# STM32WL5x_CM4 register map
File version: 1.9
CPU: CM4 r0p1, little endian, MPU, FPU, 4 interrupt priority bits
Registers are 32-bit, read-write, reset 0x0 unless marked. A register's access mark holds for its fields unless they carry their own. Offsets are from the block's base; [hi:lo] are bit positions; {n}, {i} and the like mark numbered series; 'fields as' and 'values as' point back to an identical list.

## GPIOH — General-purpose I/Os
Base 0x48001C00
0x00 MODER reset 0xC0 — GPIO port mode register
  [7:6] MODER3 — Port x configuration bits (y = 0..15)
0x04 OTYPER — GPIO port output type register
  [3] OT3 — Port x configuration bits (y = 0..15)
0x08 OSPEEDR — GPIO port output speed register
  [7:6] OSPEEDR3 — Port x configuration bits (y = 0..15)
0x0C PUPDR — GPIO port pull-up/pull-down register
  [7:6] PUPDR3 — Port x configuration bits (y = 0..15)
0x10 IDR ro — GPIO port input data register
  [3] IDR3 — Port input data (y = 0..15)
0x14 ODR — GPIO port output data register
  [3] ODR3 — Port output data (y = 0..15)
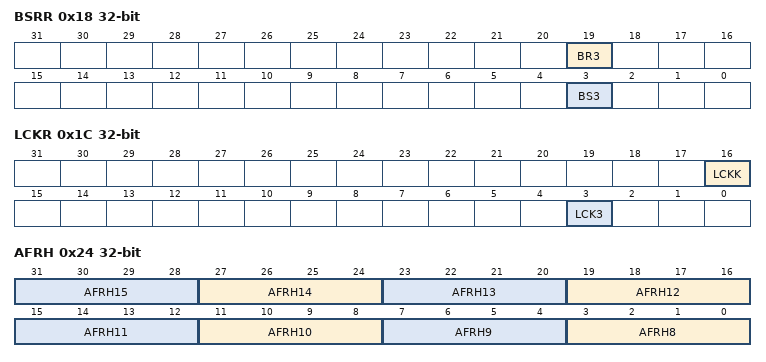
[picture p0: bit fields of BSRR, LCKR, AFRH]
0x18 BSRR wo — GPIO port bit set/reset register
  [19] BR3 — Port x reset bit y (y = 0..15)
  [3] BS3 — Port x set bit y (y= 0..15)
0x1C LCKR — GPIO port configuration lock register
  [16] LCKK — Port x lock bit y (y= 0..15)
  [3] LCK3 — Port x lock bit y (y= 0..15)
0x20 AFRL — GPIO alternate function low register
  [15:12] AFRL3 — Alternate function selection for port x bit y (y = 0..7)
0x24 AFRH — GPIO alternate function high register
  [4n-29:4n-32] AFRH{n} (n=8..15) — Alternate function selection for port x bit y (y = 8..15)
0x28 BRR — GPIO port bit reset register
  [3] BR3 — Port Reset bit

## HSEM — Hardware semaphore
Base 0x58001400
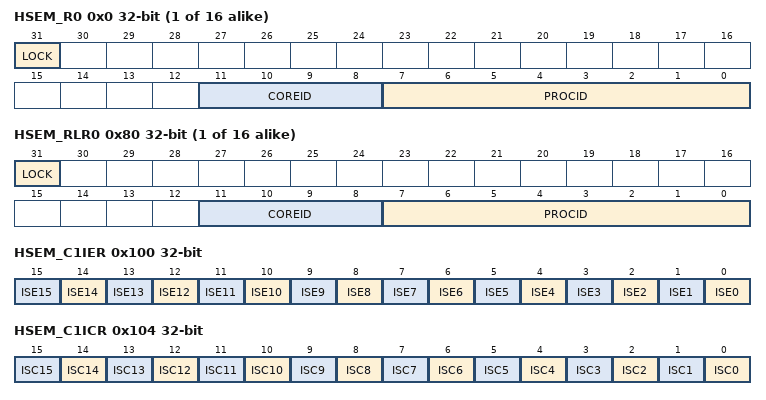
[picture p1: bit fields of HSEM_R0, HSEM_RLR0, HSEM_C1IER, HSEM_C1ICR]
{0x0+4i} HSEM_R{i} (i=0..15) — HSEM register HSEM_R0 HSEM_R31
  [31] LOCK — Lock indication
  [11:8] COREID
  [7:0] PROCID — Semaphore ProcessID
{0x80+4i} HSEM_RLR{i} ro (i=0..15) — HSEM Read lock register
  fields as HSEM_R0
0x100 HSEM_C1IER — HSEM Interrupt enable register
  [n] ISE{n} (n=0..15) — Interrupt semaphore n enable bit
0x104 HSEM_C1ICR — HSEM Interrupt clear register
  [n] ISC{n} (n=0..15) — Interrupt(N) semaphore n clear bit
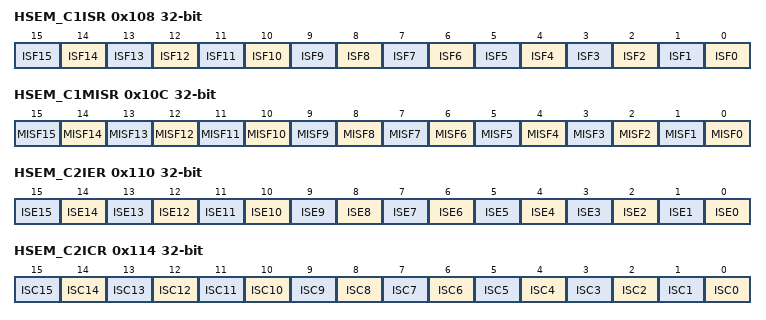
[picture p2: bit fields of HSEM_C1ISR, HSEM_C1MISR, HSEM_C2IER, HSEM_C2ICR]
0x108 HSEM_C1ISR ro — HSEM Interrupt status register
  [n] ISF{n} (n=0..15) — Interrupt(N) semaphore n status bit before enable (mask)
0x10C HSEM_C1MISR ro — HSEM Masked interrupt status register
  [n] MISF{n} (n=0..15) — masked interrupt(N) semaphore n status bit after enable (mask)
0x110 HSEM_C2IER — HSEM Interrupt enable register
  [n] ISE{n} (n=0..15) — Interrupt semaphore n enable bit
0x114 HSEM_C2ICR ro — HSEM Interrupt clear register
  [n] ISC{n} (n=0..15) — Interrupt(N) semaphore n clear bit
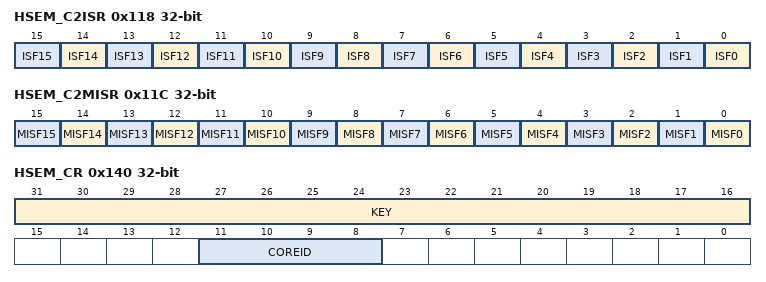
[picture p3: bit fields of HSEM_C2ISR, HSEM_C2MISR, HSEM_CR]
0x118 HSEM_C2ISR ro — HSEM Interrupt status register
  fields as HSEM_C1ISR
0x11C HSEM_C2MISR ro — HSEM Masked interrupt status register
  fields as HSEM_C1MISR
0x140 HSEM_CR wo — HSEM Clear register
  [31:16] KEY — Semaphore clear Key
  [11:8] COREID
0x144 HSEM_KEYR — HSEM Interrupt clear register
  [31:16] KEY — Semaphore Clear Key

## IPCC — Inter Processor communication controller
Base 0x58000C00
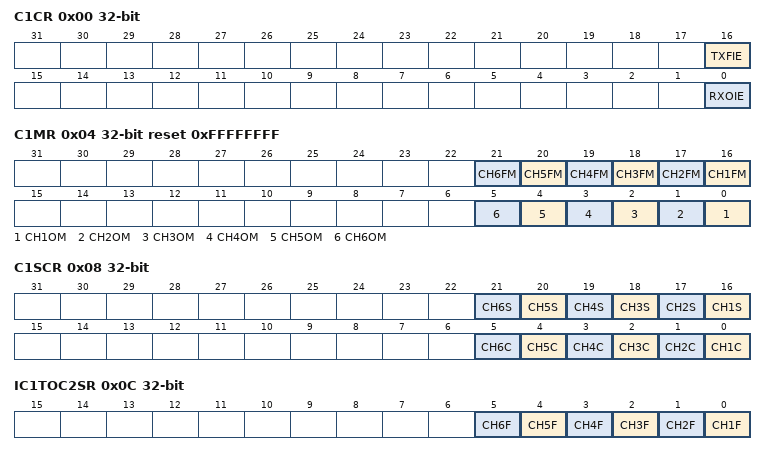
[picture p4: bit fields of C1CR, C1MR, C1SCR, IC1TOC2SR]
0x00 C1CR — IPCC Processor 1 control register
  [16] TXFIE, [0] RXOIE
0x04 C1MR reset 0xFFFFFFFF — IPCC Processor 1 mask register
  [n+15] CH{n}FM (n=1..6), [n-1] CH{n}OM (n=1..6)
0x08 C1SCR — Reading this register will always return 0x0000 0000.
  [n+15] CH{n}S (n=1..6), [n-1] CH{n}C (n=1..6)
0x0C IC1TOC2SR ro — IPCC processor 1 to processor 2 status register
  [n-1] CH{n}F (n=1..6)
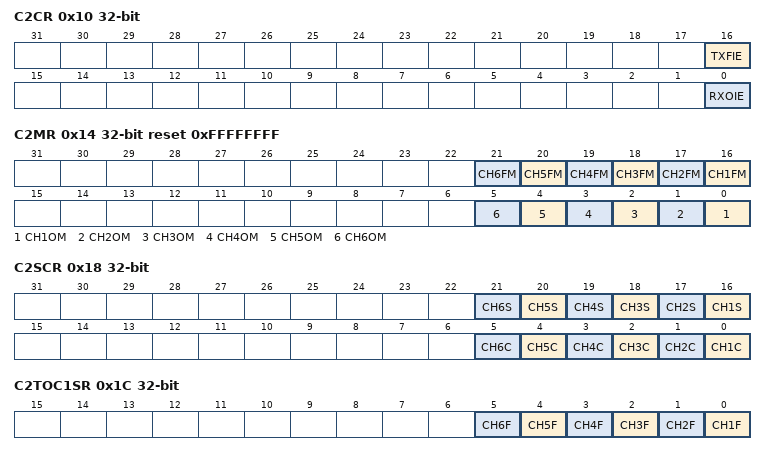
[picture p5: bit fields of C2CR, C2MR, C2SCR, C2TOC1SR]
0x10 C2CR — IPCC Processor 2 control register
  [16] TXFIE, [0] RXOIE
0x14 C2MR reset 0xFFFFFFFF — IPCC Processor 2 mask register
  [n+15] CH{n}FM (n=1..6), [n-1] CH{n}OM (n=1..6)
0x18 C2SCR — Reading this register will always return 0x0000 0000.
  [n+15] CH{n}S (n=1..6), [n-1] CH{n}C (n=1..6)
0x1C C2TOC1SR ro — IPCC processor 2 to processor 1 status register
  [n-1] CH{n}F (n=1..6)
0x3F0 HWCFGR ro reset 0x6 — IPCC Hardware configuration register
  [7:0] CHANNELS
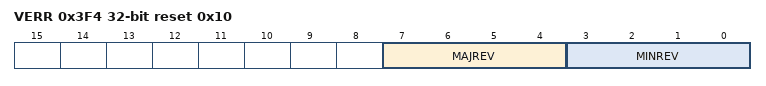
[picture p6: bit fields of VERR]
0x3F4 VERR ro reset 0x10 — IPCC IP Version register
  [7:4] MAJREV, [3:0] MINREV
0x3F8 IPIDR ro reset 0x100071 — IPCC IP Identification register
  [31:0] ID
0x3FC SIDR ro reset 0xA3C5DD01 — IPCC Size ID register
  [31:0] SID
